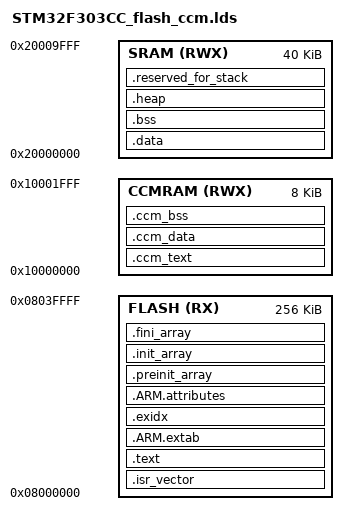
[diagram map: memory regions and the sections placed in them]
/* Generated by LinkerScriptGenerator [http://visualgdb.com/tools/LinkerScriptGenerator]
 * Target: STM32F303CC
 * The file is provided under the BSD license.
 */

ENTRY(Reset_Handler)

MEMORY
{
	FLASH (RX)   : ORIGIN = 0x08000000, LENGTH = 256K
	SRAM (RWX)   : ORIGIN = 0x20000000, LENGTH = 40K
	CCMRAM (RWX) : ORIGIN = 0x10000000, LENGTH = 8K
}

/*_estack = 0x2000a000;*/
_estack = 0x10002000; /* 0x10000000 + 8K*/

SECTIONS
{
	.isr_vector :
	{
		. = ALIGN(4);
                PROVIDE(__vtor = .);
		KEEP(*(.vectors))
		. = ALIGN(4);
	} > FLASH

	.text :
	{
		. = ALIGN(4);
		_stext = .;

		*(.text)
		*(.text*)
		*(.rodata)
		*(.rodata*)
		*(.glue_7)
		*(.glue_7t)
		KEEP(*(.init))
		KEEP(*(.fini))
		. = ALIGN(4);
		_etext = .;

	} > FLASH

	.ARM.extab :
	{
		. = ALIGN(4);
		*(.ARM.extab)
		*(.gnu.linkonce.armextab.*)
		. = ALIGN(4);
	} > FLASH

	.exidx :
	{
		. = ALIGN(4);
		PROVIDE(__exidx_start = .);
		*(.ARM.exidx*)
		. = ALIGN(4);
		PROVIDE(__exidx_end = .);
	} > FLASH

	.ARM.attributes :
	{
		*(.ARM.attributes)
	} > FLASH

	.preinit_array :
	{
		PROVIDE(__preinit_array_start = .);
		KEEP(*(.preinit_array*))
		PROVIDE(__preinit_array_end = .);
	} > FLASH

	.init_array :
	{
		PROVIDE(__init_array_start = .);
		KEEP(*(SORT(.init_array.*)))
		KEEP(*(.init_array*))
		PROVIDE(__init_array_end = .);
	} > FLASH

	.fini_array :
	{
		PROVIDE(__fini_array_start = .);
		KEEP(*(.fini_array*))
		KEEP(*(SORT(.fini_array.*)))
		PROVIDE(__fini_array_end = .);
	} > FLASH

	. = ALIGN(4);
	_sidata = .;

	.data : AT(_sidata)
	{
		. = ALIGN(4);
		_sdata = .;

		PROVIDE(__data_start__ = _sdata);
		*(.data)
		*(.data*)
		. = ALIGN(4);
		_edata = .;

		PROVIDE(__data_end__ = _edata);
	} > SRAM

	.bss :
	{
		. = ALIGN(4);
		_sbss = .;

		PROVIDE(__bss_start__ = _sbss);
		*(.bss)
		*(.bss*)
		*(COMMON)
		. = ALIGN(4);
		_ebss = .;

		PROVIDE(__bss_end__ = _ebss);
	} > SRAM
	/* --- begin generated external memory sections -- */
	/*. = _sidata + SIZEOF(.data) + SIZEOF(.bss);*/
	/*. = _sbss + SIZEOF(.bss);*/
	. = ALIGN(4);
	_siccm_text = .;

	.ccm_text : AT(_siccm_text)
	{
		. = ALIGN(4);
		_sccm_text = .;

		PROVIDE(__ccm_text_start = _sccm_text);
		*(.ccm_text)
		*(.ccm_text*)
		. = ALIGN(4);
		_eccm_text = .;

		PROVIDE(__ccm_text_end = _eccm_text);
	} > CCMRAM

	. = _siccm_text + SIZEOF(.ccm_text);
	. = ALIGN(4);
	_siccm_data = .;

	.ccm_data : AT(_siccm_data)
	{
		. = ALIGN(4);
		_sccm_data = .;

		PROVIDE(__ccm_data_start = _sccm_data);
		*(.ccm_data)
		*(.ccm_data*)
		. = ALIGN(4);
		_eccm_data = .;

		PROVIDE(__ccm_data_end = _eccm_data);
	} > CCMRAM

	.ccm_bss (NOLOAD) :
	{
		. = ALIGN(4);
		_sccm_bss = .;

		PROVIDE(__ccm_bss_start = _sccm_bss);
		*(.ccm_bss)
		*(.ccm_bss*)
		. = ALIGN(4);
		_eccm_bss = .;

		PROVIDE(__ccm_bss_end = _eccm_bss);
	} > CCMRAM

	/* --- end generated external memory sections -- */


	PROVIDE(end = .);

	.heap (NOLOAD) :
	{
		. = ALIGN(4);
		PROVIDE(__heap_start__ = .);
		KEEP(*(.heap))
		. = ALIGN(4);
		PROVIDE(__heap_end__ = .);
	} > SRAM

	.reserved_for_stack (NOLOAD) :
	{
		. = ALIGN(4);
		PROVIDE(__reserved_for_stack_start__ = .);
		KEEP(*(.reserved_for_stack))
		. = ALIGN(4);
		PROVIDE(__reserved_for_stack_end__ = .);
	} > SRAM

}

